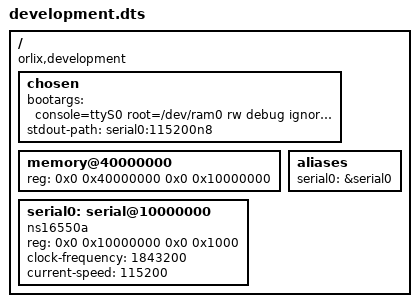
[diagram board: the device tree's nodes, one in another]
/dts-v1/;

/ {
	compatible = "orlix,development", "orlix";
	#address-cells = <2>;
	#size-cells = <2>;

	chosen {
		bootargs = "console=ttyS0 root=/dev/ram0 rw debug ignore_loglevel orlix.profile=development";
		stdout-path = "serial0:115200n8";
	};

	memory@40000000 {
		device_type = "memory";
		reg = <0x0 0x40000000 0x0 0x10000000>;
	};

	aliases {
		serial0 = &serial0;
	};

	serial0: serial@10000000 {
		compatible = "ns16550a";
		reg = <0x0 0x10000000 0x0 0x1000>;
		clock-frequency = <1843200>;
		current-speed = <115200>;
		status = "okay";
	};
};
